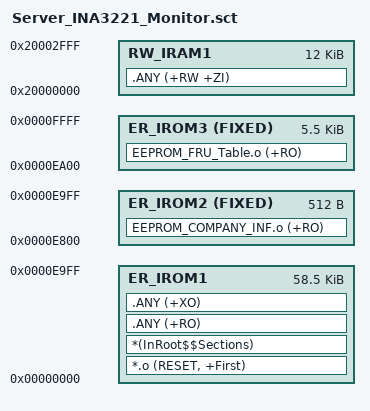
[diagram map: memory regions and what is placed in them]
; *************************************************************
; *** Scatter-Loading Description File generated by uVision ***
; *************************************************************

LR_IROM1 0x00000000 0x00010000  {    ; load region size_region
  ER_IROM1 0x00000000 0x0000EA00  {  ; load address = execution address
   *.o (RESET, +First)
   *(InRoot$$Sections)
   .ANY (+RO)
   .ANY (+XO)
  }
  RW_IRAM1 0x20000000 0x00003000  {  ; RW data
   .ANY (+RW +ZI)
  }
  ER_IROM2 0x0000E800 FIXED 0x00000200  {  ; load address = execution address
    EEPROM_COMPANY_INF.o (+RO)
  }
  
  ER_IROM3 0x0000EA00 FIXED 0x00001600  {  ; load address = execution address
    EEPROM_FRU_Table.o (+RO)
  }
}

